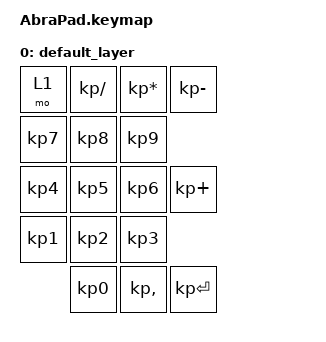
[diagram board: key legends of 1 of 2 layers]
#include <behaviors.dtsi>
#include <dt-bindings/zmk/keys.h>
#include <dt-bindings/zmk/bt.h>

/ {
    keymap {
        compatible = "zmk,keymap";

        default_layer { // Layer 0
            bindings = <
            //┌───────────────┬───────────────┬───────────────┬───────────────┐
            //│ Numlock       │ Divide        │ Multiply      │ Minus         │
                &mo 1           &kp KP_DIVIDE  &kp KP_MULTIPLY  &kp KP_MINUS                                                 
            //├───────────────┼───────────────┼───────────────┼───────────────┤
            //│       7       │       8       │      9        │ Plus          │
                &kp KP_N7       &kp KP_N8       &kp KP_N9                                               
            //├───────────────┼───────────────┼───────────────┤               │
            //│       4       │       5       │      6        │               │
                &kp KP_N4       &kp KP_N5       &kp KP_N6       &kp KP_PLUS                              
            //├───────────────┼───────────────┼───────────────┼───────────────┤
            //│       1       │       2       │      3        │ Enter         │
                &kp KP_N1       &kp KP_N2       &kp KP_N3 
            //├───────────────────────────────┼───────────────┤               │
            //│               0               │       ,       │               │
                            &kp KP_N0           &kp KP_COMMA    &kp KP_ENTER
            //└───────────────────────────────┴───────────────┴───────────────┘
            >;

            sensor-bindings = <&inc_dec_kp C_VOL_UP C_VOL_DN>;
        };

        bt_layer { //layer 1
            bindings = <
            //┌───────────────┬───────────────┬───────────────┬───────────────┐
            //│ Numlock       │ Divide        │ Multiply      │ Minus         │
                                                                &bootloader
            //├───────────────┼───────────────┼───────────────┼───────────────┤
            //│       7       │       8       │      9        │ Plus          │
                                                            
            //├───────────────┼───────────────┼───────────────┤               │
            //│       4       │       5       │      6        │               │
                &bt BT_CLR      &none           &none           &none
            //├───────────────┼───────────────┼───────────────┼───────────────┤
            //│       1       │       2       │      3        │ Enter         │
                &bt BT_SEL 0    &bt BT_SEL 1    &bt BT_SEL 2
            //├───────────────────────────────┼───────────────┤               │
            //│               0               │       ,       │               │
                        
            //└───────────────────────────────┴───────────────┴───────────────┘
            >;
        };
    };
 };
